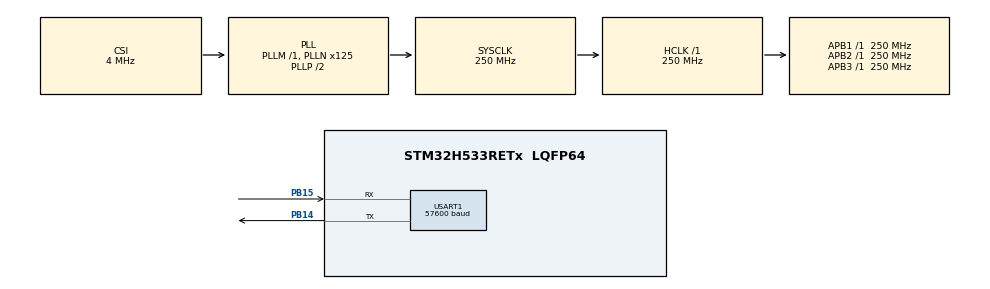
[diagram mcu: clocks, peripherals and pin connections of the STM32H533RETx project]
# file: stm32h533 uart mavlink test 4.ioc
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BOOTPATH.BootPathName=LEGACY
BOOTPATH.UserSelectedBootPath=LEGACY
CORTEX_M33_NS.userName=CORTEX_M33
GPDMA1.DESTINC_GPDMACH0=DMA_DINC_INCREMENTED
GPDMA1.IPHANDLE_GPDMACH0-SIMPLEREQUEST_GPDMACH0=__NULL
GPDMA1.IPHANDLE_GPDMACH1-SIMPLEREQUEST_GPDMACH1=__NULL
GPDMA1.REQUEST_GPDMACH0=GPDMA1_REQUEST_USART1_RX
GPDMA1.REQUEST_GPDMACH1=GPDMA1_REQUEST_USART1_TX
GPDMA1.SRCINC_GPDMACH1=DMA_SINC_INCREMENTED
Mcu.Family=STM32H5
Mcu.Name=STM32H533RETx
Mcu.Package=LQFP64
NVIC.GPDMA1_Channel0_IRQn=true\:0\:0\:false\:false\:true\:false\:true\:true
NVIC.GPDMA1_Channel1_IRQn=true\:0\:0\:false\:false\:true\:false\:true\:true
NVIC.PriorityGroup=NVIC_PRIORITYGROUP_4
NVIC.TIM1_BRK_IRQn=true\:0\:0\:false\:false\:true\:true\:true\:true
NVIC.TIM1_TRG_COM_IRQn=true\:0\:0\:false\:false\:true\:true\:true\:true
NVIC.TIM1_UP_IRQn=true\:0\:0\:false\:false\:true\:true\:true\:true
NVIC.USART1_IRQn=true\:0\:0\:false\:false\:true\:true\:true\:true
PB14.Mode=Asynchronous
PB14.Signal=USART1_TX
PB15.Mode=Asynchronous
PB15.Signal=USART1_RX
PH0-OSC_IN(PH0).Mode=HSE-External-Oscillator
PH0-OSC_IN(PH0).Signal=RCC_OSC_IN
PH1-OSC_OUT(PH1).Mode=HSE-External-Oscillator
PH1-OSC_OUT(PH1).Signal=RCC_OSC_OUT
ProjectManager.HeapSize=0x200
ProjectManager.StackSize=0x400
ProjectManager.TargetToolchain=STM32CubeIDE
RCC.ADCFreq_Value=250000000
RCC.AHBFreq_Value=250000000
RCC.APB1Freq_Value=250000000
RCC.APB1TimFreq_Value=250000000
RCC.APB2Freq_Value=250000000
RCC.APB2TimFreq_Value=250000000
RCC.APB3Freq_Value=250000000
RCC.CSI_VALUE=4000000
RCC.CortexFreq_Value=250000000
RCC.EPOD_VALUE=4000000
RCC.HCLKFreq_Value=250000000
RCC.HSE_VALUE=25000000
RCC.HSI48_VALUE=48000000
RCC.HSI_VALUE=64000000
RCC.LSE_VALUE=32768
RCC.LSIRC_VALUE=32000
RCC.PLL2FRACN=0
RCC.PLL3FRACN=0
RCC.PLLFRACN=0
RCC.PLLN=125
RCC.SYSCLKFreq_VALUE=250000000
RCC.SYSCLKSource=RCC_SYSCLKSOURCE_PLLCLK
RCC.USBFreq_Value=48000000
RCC.VCOOutputFreq_Value=500000000
TIM1.PeriodNoDither=1000-1
TIM1.Prescaler=250-1
USART1.BaudRate=57600
USART1.VirtualMode-Asynchronous=VM_ASYNC
VP_BOOTPATH_VS_BOOTPATH.Mode=BP_Activate
VP_CORTEX_M33_NS_VS_Hclk.Mode=Hclk_Mode
VP_GPDMA1_VS_GPDMACH0.Mode=SIMPLEREQUEST_GPDMACH0
VP_GPDMA1_VS_GPDMACH1.Mode=SIMPLEREQUEST_GPDMACH1
VP_ICACHE_VS_ICACHE.Mode=DefaultMode
VP_MEMORYMAP_VS_MEMORYMAP.Mode=CurAppReg
VP_PWR_VS_DBSignals.Mode=DisableDeadBatterySignals
VP_PWR_VS_LPOM.Mode=PowerOptimisation
VP_PWR_VS_SECSignals.Mode=Security/Privilege
VP_TIM1_VS_ClockSourceINT.Mode=Internal
board=custom

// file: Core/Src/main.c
/* USER CODE BEGIN Header */
/**
  ******************************************************************************
  * @file           : main.c
  * @brief          : Main program body
  ******************************************************************************
  * @attention
  *
  * Copyright (c) 2024 STMicroelectronics.
  * All rights reserved.
  *
  * This software is licensed under terms that can be found in the LICENSE file
  * in the root directory of this software component.
  * If no LICENSE file comes with this software, it is provided AS-IS.
  *
  ******************************************************************************
  */
/* USER CODE END Header */
#include "main.h"

/* USER CODE BEGIN Includes */
#include"checksum.h"
#include"test_msg/mavlink.h"
#include"test_msg/test_msg.h"
/* USER CODE END Includes */

/* USER CODE BEGIN PM */
#define component_id 0x01
#define system_id 0x01
/* USER CODE END PM */

TIM_HandleTypeDef htim1;

UART_HandleTypeDef huart1;
DMA_HandleTypeDef handle_GPDMA1_Channel1;
DMA_HandleTypeDef handle_GPDMA1_Channel0;

/* USER CODE BEGIN PV */
mavlink_message_t msg;
mavlink_test_t test_msg;
uint16_t msg_length;
uint32_t timer;
/* USER CODE END PV */

void SystemClock_Config(void);
static void MX_GPIO_Init(void);
static void MX_GPDMA1_Init(void);
static void MX_ICACHE_Init(void);
static void MX_TIM1_Init(void);
static void MX_USART1_UART_Init(void);

/* USER CODE BEGIN 0 */
void HAL_TIM_PeriodElapsedCallback(TIM_HandleTypeDef *htim)
{
  UNUSED(htim);
  if(htim->Instance == TIM1){
		  test_msg.time_boot_ms ++;
		  timer++;
		  if(timer == 100){
			  msg_length = mavlink_msg_test_encode(system_id, component_id, &msg, &test_msg);
			  HAL_UART_Transmit_DMA(&huart1, &msg, msg_length);
			  timer =0;
		  }
  }
}
/* USER CODE END 0 */

int main(void)
{

  /* MCU Configuration--------------------------------------------------------*/

  /* Reset of all peripherals, Initializes the Flash interface and the Systick. */
  HAL_Init();

  /* Configure the system clock */
  SystemClock_Config();

  /* Initialize all configured peripherals */
  MX_GPIO_Init();
  MX_GPDMA1_Init();
  MX_ICACHE_Init();
  MX_TIM1_Init();
  MX_USART1_UART_Init();
  /* USER CODE BEGIN 2 */
  test_msg.roll = 5;
  test_msg.pitch = 10;
  test_msg.yaw = 7;
  test_msg.lat = 108;
  test_msg.lon= 21;
  test_msg.temperature = 23;

  HAL_TIM_Base_Start_IT(&htim1);
  msg_length = mavlink_msg_test_encode(system_id, component_id, &msg, &test_msg);
  /* USER CODE END 2 */

  /* Infinite loop */
  while (1)
  {

  }
}

void SystemClock_Config(void)
{
  RCC_OscInitTypeDef RCC_OscInitStruct = {0};
  RCC_ClkInitTypeDef RCC_ClkInitStruct = {0};

  /** Configure the main internal regulator output voltage
  */
  __HAL_PWR_VOLTAGESCALING_CONFIG(PWR_REGULATOR_VOLTAGE_SCALE0);

  while(!__HAL_PWR_GET_FLAG(PWR_FLAG_VOSRDY)) {}

  /** Initializes the RCC Oscillators according to the specified parameters
  * in the RCC_OscInitTypeDef structure.
  */
  RCC_OscInitStruct.OscillatorType = RCC_OSCILLATORTYPE_CSI;
  RCC_OscInitStruct.CSIState = RCC_CSI_ON;
  RCC_OscInitStruct.CSICalibrationValue = RCC_CSICALIBRATION_DEFAULT;
  RCC_OscInitStruct.PLL.PLLState = RCC_PLL_ON;
  RCC_OscInitStruct.PLL.PLLSource = RCC_PLL1_SOURCE_CSI;
  RCC_OscInitStruct.PLL.PLLM = 1;
  RCC_OscInitStruct.PLL.PLLN = 125;
  RCC_OscInitStruct.PLL.PLLP = 2;
  RCC_OscInitStruct.PLL.PLLQ = 2;
  RCC_OscInitStruct.PLL.PLLR = 2;
  RCC_OscInitStruct.PLL.PLLRGE = RCC_PLL1_VCIRANGE_2;
  RCC_OscInitStruct.PLL.PLLVCOSEL = RCC_PLL1_VCORANGE_WIDE;
  RCC_OscInitStruct.PLL.PLLFRACN = 0;
  if (HAL_RCC_OscConfig(&RCC_OscInitStruct) != HAL_OK)
  {
    Error_Handler();
  }

  /** Initializes the CPU, AHB and APB buses clocks
  */
  RCC_ClkInitStruct.ClockType = RCC_CLOCKTYPE_HCLK|RCC_CLOCKTYPE_SYSCLK
                              |RCC_CLOCKTYPE_PCLK1|RCC_CLOCKTYPE_PCLK2
                              |RCC_CLOCKTYPE_PCLK3;
  RCC_ClkInitStruct.SYSCLKSource = RCC_SYSCLKSOURCE_PLLCLK;
  RCC_ClkInitStruct.AHBCLKDivider = RCC_SYSCLK_DIV1;
  RCC_ClkInitStruct.APB1CLKDivider = RCC_HCLK_DIV1;
  RCC_ClkInitStruct.APB2CLKDivider = RCC_HCLK_DIV1;
  RCC_ClkInitStruct.APB3CLKDivider = RCC_HCLK_DIV1;

  if (HAL_RCC_ClockConfig(&RCC_ClkInitStruct, FLASH_LATENCY_5) != HAL_OK)
  {
    Error_Handler();
  }

  /** Configure the programming delay
  */
  __HAL_FLASH_SET_PROGRAM_DELAY(FLASH_PROGRAMMING_DELAY_2);
}

static void MX_GPDMA1_Init(void)
{

  /* Peripheral clock enable */
  __HAL_RCC_GPDMA1_CLK_ENABLE();

  /* GPDMA1 interrupt Init */
    HAL_NVIC_SetPriority(GPDMA1_Channel0_IRQn, 0, 0);
    HAL_NVIC_EnableIRQ(GPDMA1_Channel0_IRQn);
    HAL_NVIC_SetPriority(GPDMA1_Channel1_IRQn, 0, 0);
    HAL_NVIC_EnableIRQ(GPDMA1_Channel1_IRQn);

}

static void MX_ICACHE_Init(void)
{

  /** Enable instruction cache (default 2-ways set associative cache)
  */
  if (HAL_ICACHE_Enable() != HAL_OK)
  {
    Error_Handler();
  }

}

static void MX_TIM1_Init(void)
{

  TIM_ClockConfigTypeDef sClockSourceConfig = {0};
  TIM_MasterConfigTypeDef sMasterConfig = {0};

  htim1.Instance = TIM1;
  htim1.Init.Prescaler = 250-1;
  htim1.Init.CounterMode = TIM_COUNTERMODE_UP;
  htim1.Init.Period = 999;
  htim1.Init.ClockDivision = TIM_CLOCKDIVISION_DIV1;
  htim1.Init.RepetitionCounter = 0;
  htim1.Init.AutoReloadPreload = TIM_AUTORELOAD_PRELOAD_DISABLE;
  if (HAL_TIM_Base_Init(&htim1) != HAL_OK)
  {
    Error_Handler();
  }
  sClockSourceConfig.ClockSource = TIM_CLOCKSOURCE_INTERNAL;
  if (HAL_TIM_ConfigClockSource(&htim1, &sClockSourceConfig) != HAL_OK)
  {
    Error_Handler();
  }
  sMasterConfig.MasterOutputTrigger = TIM_TRGO_RESET;
  sMasterConfig.MasterOutputTrigger2 = TIM_TRGO2_RESET;
  sMasterConfig.MasterSlaveMode = TIM_MASTERSLAVEMODE_DISABLE;
  if (HAL_TIMEx_MasterConfigSynchronization(&htim1, &sMasterConfig) != HAL_OK)
  {
    Error_Handler();
  }

}

static void MX_USART1_UART_Init(void)
{

  huart1.Instance = USART1;
  huart1.Init.BaudRate = 57600;
  huart1.Init.WordLength = UART_WORDLENGTH_8B;
  huart1.Init.StopBits = UART_STOPBITS_1;
  huart1.Init.Parity = UART_PARITY_NONE;
  huart1.Init.Mode = UART_MODE_TX_RX;
  huart1.Init.HwFlowCtl = UART_HWCONTROL_NONE;
  huart1.Init.OverSampling = UART_OVERSAMPLING_16;
  huart1.Init.OneBitSampling = UART_ONE_BIT_SAMPLE_DISABLE;
  huart1.Init.ClockPrescaler = UART_PRESCALER_DIV1;
  huart1.AdvancedInit.AdvFeatureInit = UART_ADVFEATURE_NO_INIT;
  if (HAL_UART_Init(&huart1) != HAL_OK)
  {
    Error_Handler();
  }
  if (HAL_UARTEx_SetTxFifoThreshold(&huart1, UART_TXFIFO_THRESHOLD_1_8) != HAL_OK)
  {
    Error_Handler();
  }
  if (HAL_UARTEx_SetRxFifoThreshold(&huart1, UART_RXFIFO_THRESHOLD_1_8) != HAL_OK)
  {
    Error_Handler();
  }
  if (HAL_UARTEx_DisableFifoMode(&huart1) != HAL_OK)
  {
    Error_Handler();
  }

}

static void MX_GPIO_Init(void)
{

  /* GPIO Ports Clock Enable */
  __HAL_RCC_GPIOH_CLK_ENABLE();
  __HAL_RCC_GPIOB_CLK_ENABLE();

}

void Error_Handler(void)
{
  __disable_irq();
  while (1)
  {
  }
}
